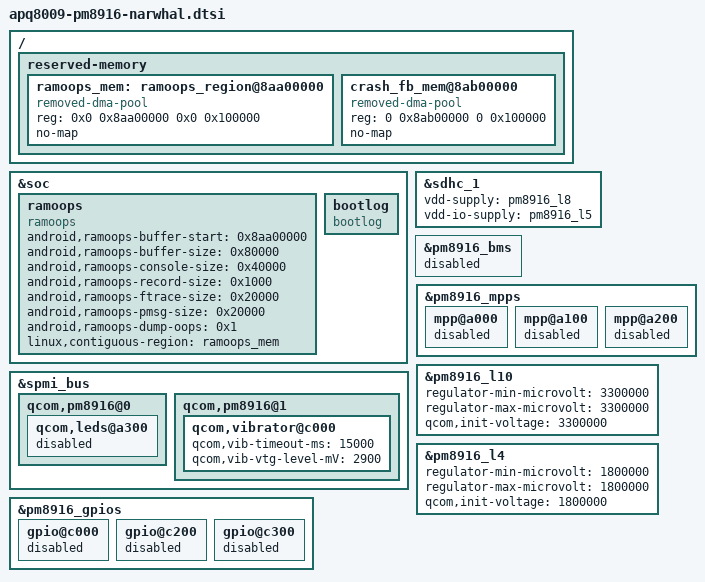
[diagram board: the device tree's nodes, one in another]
/* Copyright (c) 2017, LGE Inc. All rights reserved.
 *
 * This program is free software; you can redistribute it and/or modify
 * it under the terms of the GNU General Public License version 2 and
 * only version 2 as published by the Free Software Foundation.
 *
 * This program is distributed in the hope that it will be useful,
 * but WITHOUT ANY WARRANTY; without even the implied warranty of
 * MERCHANTABILITY or FITNESS FOR A PARTICULAR PURPOSE.  See the
 * GNU General Public License for more details.
 */

#include "apq8009-narwhal-pm.dtsi"
#include "apq8009-narwhal-movement.dtsi"

/ {
	reserved-memory {
		ramoops_mem: ramoops_region@8aa00000 {
			reg = <0x0 0x8aa00000 0x0 0x100000>;
			compatible = "removed-dma-pool";
			no-map;
		};

		crash_fb_mem@8ab00000 {
			reg = <0 0x8ab00000 0 0x100000>;
			compatible = "removed-dma-pool";
			no-map;
		};
	};
};

&soc {
	ramoops {
		compatible = "ramoops";
		status = "ok";

		android,ramoops-buffer-start = <0x8aa00000>;
		android,ramoops-buffer-size = <0x80000>;
		android,ramoops-console-size = <0x40000>;
		android,ramoops-record-size = <0x1000>;
		android,ramoops-ftrace-size = <0x20000>;
		android,ramoops-pmsg-size = <0x20000>;
		android,ramoops-dump-oops = <0x1>;
		linux,contiguous-region = <&ramoops_mem>;
	};

	bootlog {
		compatible = "bootlog";
	};
};

&sdhc_1 {
	vdd-supply = <&pm8916_l8>;
	vdd-io-supply = <&pm8916_l5>;
};

&pm8916_bms {
	status = "disabled";
};

&spmi_bus {
	qcom,pm8916@0 {
		qcom,leds@a300 {
			status = "disabled";
		};
	};

	qcom,pm8916@1 {
		qcom,vibrator@c000 {
			status = "okay";
			qcom,vib-timeout-ms = <15000>;
			qcom,vib-vtg-level-mV = <2900>;
		};
	};
};

&pm8916_mpps {
	mpp@a000 { /* MPP 1 */
		/* VDD_PX */
		status = "disabled";
	};

	mpp@a100 { /* MPP 2 */
		/* HR LED */
		status = "disabled";
	};

	mpp@a200 { /* MPP 3 */
		/* VREF DAC */
		status = "disabled";
	};
};

&pm8916_gpios {
	gpio@c000 { /* GPIO 1 */
		/* Battery UICC Alarm */
		status = "disabled";
	};

	gpio@c200 { /* GPIO 3 */
		/* External regulator control for WTR */
		status = "disabled";
	};

	gpio@c300 { /* GPIO 4 */
		/* External regulator control for APC */
		status = "disabled";
	};
};

&pm8916_l10 {
	regulator-min-microvolt = <3300000>;
	regulator-max-microvolt = <3300000>;
	qcom,init-voltage = <3300000>;
	status = "okay";
};

&pm8916_l4 {
	regulator-min-microvolt = <1800000>;
	regulator-max-microvolt = <1800000>;
	qcom,init-voltage = <1800000>;
	status = "okay";
};
